# max78000 register map
Vendor: Maxim-Integrated; Series: ARMCM4; File version: 1.0
CPU: CM4 r2p1, little endian, MPU, FPU, 3 interrupt priority bits
Registers are 32-bit, read-write, reset 0x0 unless marked. A register's access mark holds for its fields unless they carry their own. Offsets are from the block's base; [hi:lo] are bit positions; {n}, {i} and the like mark numbered series.

## CRC — CRC Registers.
Base 0x4000F000
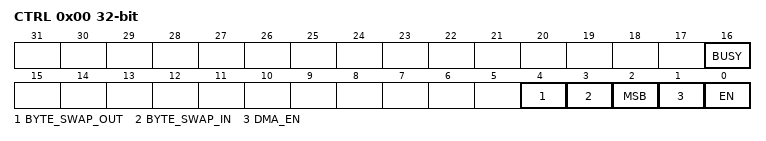
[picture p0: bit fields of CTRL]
0x00 CTRL — CRC Control
  [16] BUSY — CRC Busy
  [4] BYTE_SWAP_OUT — Byte Swap CRC Value Output
  [3] BYTE_SWAP_IN — Byte Swap CRC Data Input
  [2] MSB — MSB Select
  [1] DMA_EN — DMA Request Enable
  [0] EN — CRC Enable
0x04 DATAIN32 — CRC Data Input
  [31:0] DATA — CRC Data
0x04 DATAIN16 16-bit — CRC Data Input
  [15:0] DATA — CRC Data
0x04 DATAIN8 8-bit — CRC Data Input
  [7:0] DATA — CRC Data
0x08 POLY — CRC Polynomial
0x0C VAL — Current CRC Value
  [31:0] VALUE

## FCR — Function Control Register.
Base 0x40000800
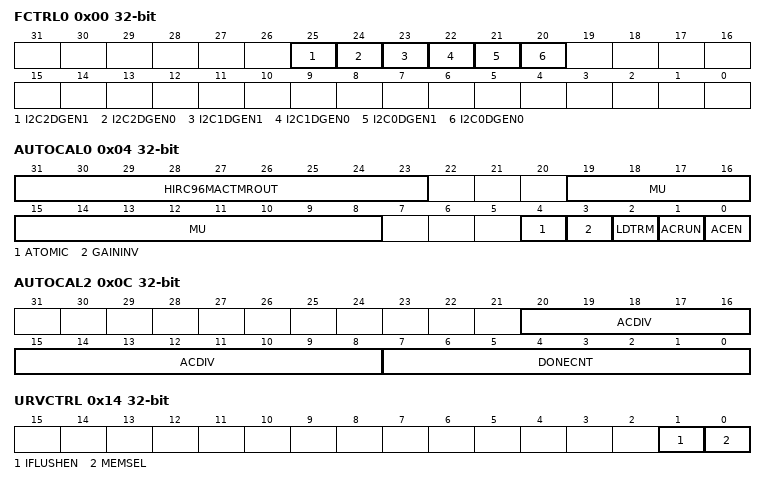
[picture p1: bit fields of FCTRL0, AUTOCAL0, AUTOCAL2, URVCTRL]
0x00 FCTRL0 — Function Control 0.
  [all] fields
    0=dis (Deglitcher disabled.); 1=en (Deglitcher enabled.)
  [25] I2C2DGEN1 — I2C2 SCL Pad Deglitcher enable.
  [24] I2C2DGEN0 — I2C2 SDA Pad Deglitcher enable.
  [23] I2C1DGEN1 — I2C1 SCL Pad Deglitcher enable.
  [22] I2C1DGEN0 — I2C1 SDA Pad Deglitcher enable.
  [21] I2C0DGEN1 — I2C0 SCL Pad Deglitcher enable.
  [20] I2C0DGEN0 — I2C0 SDA Pad Deglitcher enable.
0x04 AUTOCAL0 — Automatic Calibration 0.
  [31:23] HIRC96MACTMROUT — HIRC96M Trim Value.
  [19:8] MU — MU value.
  [4] ATOMIC — Atomic mode.
    0=not (Not Running.); 1=run (Running.)
  [3] GAININV — Invert Gain.
    0=not (Not Running.); 1=run (Running.)
  [2] LDTRM — Load Trim.
  [1] ACRUN — Autocalibration Run.
    0=not (Not Running.); 1=run (Running.)
  [0] ACEN — Auto-calibration Enable.
    0=dis (Disabled.); 1=en (Enabled.)
0x08 AUTOCAL1 — Automatic Calibration 1.
  [8:0] INITTRM — Initial Trim Setting.
0x0C AUTOCAL2 — Automatic Calibration 2
  [20:8] ACDIV — Auto-callibration Div Setting.
  [7:0] DONECNT — Auto-callibration Done Counter Setting.
0x10 URVBOOTADDR — RISC-V Boot Address.
0x14 URVCTRL — RISC-V Control Register.
  [1] IFLUSHEN — URV instruction flush enable.
  [0] MEMSEL — RAM2, RAM3 exclusive ownership.

## FLC — Flash Memory Control.
Base 0x40029000; register names take the prefix FLSH_
0x00 ADDR — Flash Write Address.
  [31:0] ADDR — Address for next operation.
0x04 CLKDIV reset 0x64 — Flash Clock Divide. The clock (PLL0) is divided by this value to generate a 1 MHz clock for Flash controller.
  [7:0] CLKDIV — Flash Clock Divide. The clock is divided by this value to generate a 1MHz clock for flash controller.
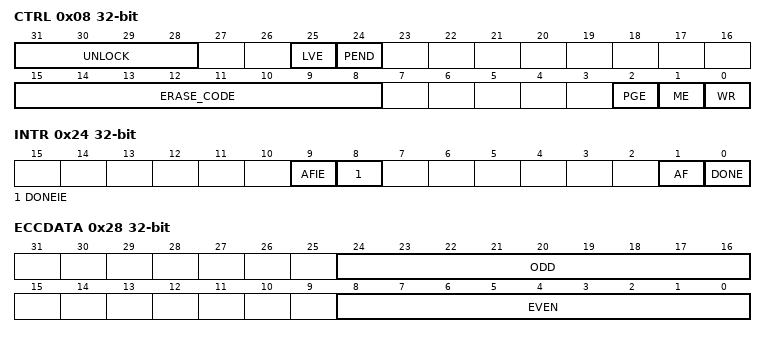
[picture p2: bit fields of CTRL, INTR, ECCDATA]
0x08 CTRL — Flash Control Register.
  [31:28] UNLOCK — Flash Unlock. The correct unlock code must be written to these four bits before any Flash write or erase operation is allowed.
    2=unlocked (Flash Unlocked.); 3=locked (Flash Locked.)
  [25] LVE — Low Voltage enable.
  [24] PEND ro — Flash Pending. When Flash operation is in progress (busy), Flash reads and writes will fail. When PEND is set, write to all Flash registers, with exception of the Flash interrupt register, are ignored.
    0=idle; 1=busy
  [15:8] ERASE_CODE — Erase Code. The ERASE_CODE must be set up property before erase operation can be initiated. These bits are automatically cleared after the operation is complete.
    0=nop (No operation.); 85=erasePage (Enable Page Erase.); 170=eraseAll (Enable Mass Erase. The debug port must be enabled.)
  [2] PGE — Page Erase. This bit is automatically cleared after the operation.
    0=complete (No operation/complete.); 1=Start operation
  [1] ME — Mass Erase. This bit is automatically cleared after the operation.
    0=complete (No operation/complete.); 1=Start operation
  [0] WR — Write. This bit is automatically cleared after the operation.
    0=complete (No operation/complete.); 1=Start operation
0x24 INTR — Flash Interrupt Register.
  [9] AFIE — Flash Done Interrupt Enable.
    0=disable; 1=enable
  [8] DONEIE — Flash Done Interrupt Enable.
    0=disable; 1=enable
  [1] AF — Flash Access Fail. This bit is set when an attempt is made to write the flash while the flash is busy or the flash is locked. This bit can only be set to 1 by hardware.
    0=noError (No Failure.); 1=error (Failure occurs.)
  [0] DONE — Flash Done Interrupt. This bit is set to 1 upon Flash write or erase completion.
    0=inactive (No interrupt is pending.); 1=pending (An interrupt is pending.)
0x28 ECCDATA
  [24:16] ODD — Error Correction Code Even Data.
  [8:0] EVEN — Error Correction Code Odd Data.
{0x30+4i} DATA[{i}] (i=0..3) — Flash Write Data.
  [31:0] DATA — Data next operation.
0x40 ACTRL wo — Access Control Register. Writing the ACTRL register with the following values in the order shown, allows read and write access to the system and user Information block: pflc-actrl = 0x3a7f5ca3; pflc-actrl = 0xa1e34f20; pflc-actrl = 0x9608b2c1. When unlocked, a write of any word will disable access to system and user information block. Readback of this register is always zero.
  [31:0] ACTRL — Access control.
0x80 WELR0
  [31:0] WELR0 — Access control.
0x88 WELR1
  [31:0] WELR1 — Access control.
0x90 RLR0
  [31:0] RLR0 — Access control.
0x98 RLR1
  [31:0] RLR1 — Access control.
